# CC1312PSIP register map
File version: 1.0
CPU: CM4 1.0, other endian, MPU, FPU, 3 interrupt priority bits
Registers are 32-bit, read-write, reset 0x0 unless marked. A register's access mark holds for its fields unless they carry their own. Offsets are from the block's base; [hi:lo] are bit positions; {n}, {i} and the like mark numbered series; <NAME> marks a mode.

## AUX_ANAIF — AUX Analog Interface (AUX_ANAIF) encapsulates direct data and control interfaces between AUX digital and AUX analog circuits. It lets AUX_SCE, UDMA0, and system CPU: -Trigger ADC sample and conversion process. - Write ADC samples to FIFO. - Charge analog nodes by the use of the analog ISRC module. See ADI_4_AUX:ISRC and ADI_4_AUX:COMP.COMPA_REF_CURR_EN for further information. - Use the DAC to generate a programmable voltage on COMPB_REF, COMPA_REF, or COMPA_IN analog nodes. To use: - ADC : AUX_SCE must request active operational mode with AON_PMCTL:AUXSCECLK.SRC set to SCLK_HFDIV2. There are no requirements for system CPU. - ISRC : AUX_SCE must request active operational mode. There are no requirements for system CPU. - DAC : AUX_SCE must set AUX_SYSIF:PEROPRATE.ANAIF_DAC_OP_RATE to SCE_RATE as long as DAC state machine generates the sample clock. System CPU must set AUX_SYSIF:PEROPRATE.ANAIF_DAC_OP_RATE to BUS_RATE as long as DAC state machine generates the sample clock. See DACSMPLCTL.EN for further information.
Base 0x400C9000
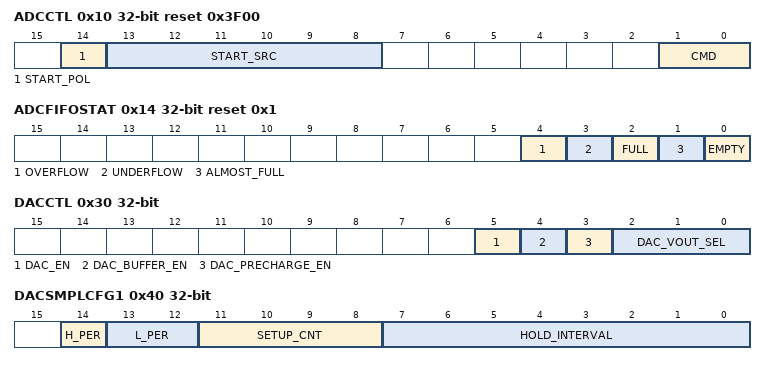
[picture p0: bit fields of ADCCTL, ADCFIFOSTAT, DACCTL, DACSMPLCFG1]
0x10 ADCCTL reset 0x3F00 — ADC Control Configuration of ADI_4_AUX:ADC0.SMPL_MODE decides if the ADC trigger starts sampling or conversion.
  [14] START_POL — [14:14] Select active polarity for START_SRC event.
    1=FALL (Set ADC trigger on falling edge of event source.); 0=RISE (Set ADC trigger on rising edge of event source.)
  [13:8] START_SRC — [13:8] Select ADC trigger event source from the asynchronous AUX event bus. Set START_SRC to NO_EVENT if you want to trigger the ADC manually through ADCTRIG.START. If you write a non-enumerated value the behavior is identical to NO_EVENT. The written value is returned when read.
    63=NO_EVENT; 61=AUX_SMPH_AUTOTAKE_DONE (AUX_EVCTL:EVSTAT3.AUX_SMPH_AUTOTAKE_DONE); 56=AUX_ISRC_RESET_N (AUX_EVCTL:EVSTAT3.AUX_ISRC_RESET_N); 55=AUX_TDC_DONE (AUX_EVCTL:EVSTAT3.AUX_TDC_DONE); 54=AUX_TIMER0_EV (AUX_EVCTL:EVSTAT3.AUX_TIMER0_EV); 53=AUX_TIMER1_EV (AUX_EVCTL:EVSTAT3.AUX_TIMER1_EV); 52=AUX_TIMER2_PULSE (AUX_EVCTL:EVSTAT3.AUX_TIMER2_PULSE); {v}=AUX_TIMER2_EV{v-48} (AUX_EVCTL:EVSTAT3.AUX_TIMER2_EV{v-48}) (v=48..51); 47=AUX_COMPB (AUX_EVCTL:EVSTAT2.AUX_COMPB); 46=AUX_COMPA (AUX_EVCTL:EVSTAT2.AUX_COMPA); 43=MCU_EV (AUX_EVCTL:EVSTAT2.MCU_EV); 42=ACLK_REF (AUX_EVCTL:EVSTAT2.ACLK_REF); 41=VDDR_RECHARGE (AUX_EVCTL:EVSTAT2.VDDR_RECHARGE); 40=MCU_ACTIVE (AUX_EVCTL:EVSTAT2.MCU_ACTIVE); 39=PWR_DWN (AUX_EVCTL:EVSTAT2.PWR_DWN); 38=SCLK_LF (AUX_EVCTL:EVSTAT2.SCLK_LF); 37=AON_BATMON_TEMP_UPD (AUX_EVCTL:EVSTAT2.AON_BATMON_TEMP_UPD); 36=AON_BATMON_BAT_UPD (AUX_EVCTL:EVSTAT2.AON_BATMON_BAT_UPD); 35=AON_RTC_4KHZ (AUX_EVCTL:EVSTAT2.AON_RTC_4KHZ); 34=AON_RTC_CH2_DLY (AUX_EVCTL:EVSTAT2.AON_RTC_CH2_DLY); 33=AON_RTC_CH2 (AUX_EVCTL:EVSTAT2.AON_RTC_CH2); 32=MANUAL_EV (AUX_EVCTL:EVSTAT2.MANUAL_EV); {v}=AUXIO{v} (AUX_EVCTL:EVSTAT1.AUXIO{v}) (v=16..31); {v}=AUXIO{v} (AUX_EVCTL:EVSTAT0.AUXIO{v}) (v=0..15)
  [1:0] CMD — [1:0] ADC interface command. Non-enumerated values are not supported. The written value is returned when read.
    3=FLUSH (Flush ADC FIFO. You must set CMD to EN or DIS after flush. System CPU must wait two clock cycles before it sets CMD to EN or DIS.); 1=EN (Enable ADC interface.); 0=DIS (Disable ADC interface.)
0x14 ADCFIFOSTAT reset 0x1 — ADC FIFO Status FIFO can hold up to four ADC samples.
  [4] OVERFLOW ro — [4:4] FIFO overflow flag. 0: FIFO has not overflowed. 1: FIFO has overflowed, this flag is sticky until you flush the FIFO. When the flag is set, the ADC FIFO write pointer is static. It is not possible to add more samples to the ADC FIFO. Flush FIFO to clear the flag.
  [3] UNDERFLOW ro — [3:3] FIFO underflow flag. 0: FIFO has not underflowed. 1: FIFO has underflowed, this flag is sticky until you flush the FIFO. When the flag is set, the ADC FIFO read pointer is static. Read returns the previous sample that was read. Flush FIFO to clear the flag.
  [2] FULL ro — [2:2] FIFO full flag. 0: FIFO is not full, there is less than 4 samples in the FIFO. 1: FIFO is full, there are 4 samples in the FIFO. When the flag is set, it is not possible to add more samples to the ADC FIFO. An attempt to add samples sets the OVERFLOW flag.
  [1] ALMOST_FULL ro — [1:1] FIFO almost full flag. 0: There are less than 3 samples in the FIFO, or the FIFO is full. The FULL flag is also asserted in the latter case. 1: There are 3 samples in the FIFO, there is room for one more sample.
  [0] EMPTY ro — [0:0] FIFO empty flag. 0: FIFO contains one or more samples. 1: FIFO is empty. When the flag is set, read returns the previous sample that was read and sets the UNDERFLOW flag.
0x18 ADCFIFO
  [11:0] DATA — [11:0] FIFO data. Read: Get oldest ADC sample from FIFO. Write: Write dummy sample to FIFO. This is useful for code development when you do not have real ADC samples.
0x1C ADCTRIG — ADC Trigger
  [0] START wo — [0:0] Manual ADC trigger. 0: No effect. 1: Single ADC trigger. To manually trigger the ADC, you must set ADCCTL.START_SRC to NO_EVENT to avoid conflict with event-driven ADC trigger.
0x20 ISRCCTL reset 0x1 — Current Source Control
  [0] RESET_N — [0:0] ISRC reset control. 0: ISRC drives 0 uA. 1: ISRC drives current ADI_4_AUX:ISRC.TRIM to COMPA_IN.
0x30 DACCTL — DAC Control This register controls the analog part of the DAC.
  [5] DAC_EN — [5:5] DAC module enable. 0: Disable DAC. 1: Enable DAC. The Sensor Controller must not use the DAC when AUX_SYSIF:OPMODEREQ.REQ equals PDA. The System CPU must not use the DAC when AUX_SYSIF:OPMODEREQ.REQ equals PDA in Standby TI-RTOS power mode. The System CPU must set AUX_SYSIF:PEROPRATE.ANAIF_DAC_OP_RATE to BUS_RATE to use the DAC in Active and Idle TI-RTOS power modes.
  [4] DAC_BUFFER_EN — [4:4] DAC buffer enable. DAC buffer reduces the time required to produce the programmed voltage at the expense of increased current consumption. 0: Disable DAC buffer. 1: Enable DAC buffer. Enable buffer when DAC_VOUT_SEL equals COMPA_IN. Do not enable the buffer when AUX_SYSIF:OPMODEREQ.REQ equals PDA or PDLP.
  [3] DAC_PRECHARGE_EN — [3:3] DAC precharge enable. Only enable precharge when ADI_4_AUX:MUX2.DAC_VREF_SEL equals DCOUPL and VDDS is higher than 2.65 V. DAC output voltage range: 0: 0 V to 1.28 V. 1: 1.28 V to 2.56 V. Otherwise, see ADI_4_AUX:MUX2.DAC_VREF_SEL for DAC output voltage range. Enable precharge 1 us before you enable the DAC and the buffer.
  [2:0] DAC_VOUT_SEL — [2:0] DAC output connection. An analog node must only have one driver. Other drivers for the following analog nodes are configured in [ANATOP_MMAP::ADI_4_AUX:*].
    4=COMPA_IN (Connect to COMPA_IN analog node. Required setting to drive external load selected in ADI_4_AUX:MUX1.COMPA_IN.); 2=COMPA_REF (Connect to COMPA_REF analog node. It is not possible to drive external loads connected to COMPA_REF I/O mux with this setting.); 1=COMPB_REF (Connect to COMPB_REF analog node. Required setting to use Comparator B.); 0=NC (Connect to nothing It is recommended to use NC as intermediate step when you change DAC_VOUT_SEL.)
0x34 LPMBIASCTL — Low Power Mode Bias Control The low power mode bias module provides bias current to DAC and Comparator A when AUX_SYSIF:OPMODEREQ.REQ differers from A.
  [0] EN — [0:0] Module enable. 0: Disable low power mode bias module. 1: Enable low power mode bias module. Set EN to 1 15 us before you enable the DAC or Comparator A.
0x38 DACSMPLCTL — DAC Sample Control The DAC sample clock maintains the DAC voltage stored in the sample-and-hold capacitor. The DAC sample clock waveform consists of a setup phase followed by a hold phase. In the setup phase the sample-and-hold capacitor charges to the programmed voltage. The hold phase maintains the voltage with minimal power. DACSMPLCFG0 and DACSMPLCFG1 configure the DAC sample clock waveform.
  [0] EN — [0:0] DAC sample clock enable. 0: Disable sample clock. The sample clock stops low and DACSTAT becomes 0 when the current sample clock period completes. 1: Enable DAC sample clock. DACSTAT must be 0 before you enable sample clock.
0x3C DACSMPLCFG0 — DAC Sample Configuration 0
  [5:0] CLKDIV — [5:0] Clock division. AUX_SYSIF:PEROPRATE.ANAIF_DAC_OP_RATE divided by (CLKDIV + 1) determines the sample clock base frequency. 0: Divide by 1. 1: Divide by 2. ... 63: Divide by 64.
0x40 DACSMPLCFG1 — DAC Sample Configuration 1 The sample clock period equals (high time + low time) * base period. DACSMPLCFG0.CLKDIV determines the base period. Timing requirements (DAC Buffer On / DAC Buffer Off): - (high time + low time) * base period > (4 us / 1 us) - (high time * base period) > (2 us / 0.5 us) - (low time * base period) > (2 us / 0.5 us) - (low time * base period + HOLD_INTERVAL * sample clock period) < 32 us If AUX_SYSIF:OPMODEREQ.REQ equals PDLP, you must set: - H_PER = L_PER = HOLD_INTERVAL = 0.
  [14] H_PER — [14:14] High time. The sample clock period is high for this many base periods. 0: 2 periods 1: 4 periods
  [13:12] L_PER — [13:12] Low time. The sample clock period is low for this many base periods. 0: 1 period 1: 2 periods 2: 3 periods 3: 4 periods
  [11:8] SETUP_CNT — [11:8] Setup count. Number of active sample clock periods during the setup phase. 0: 1 sample clock period 1: 2 sample clock periods ... 15 : 16 sample clock periods
  [7:0] HOLD_INTERVAL — [7:0] Hold interval. Number of inactive sample clock periods between each active sample clock period during hold phase. The sample clock is low when inactive. The range is 0 to 255.
0x44 DACVALUE
  [7:0] VALUE — [7:0] DAC value. Digital data word for the DAC. Only change VALUE when DACCTL.DAC_EN is 0. Then wait 1 us before you enable the DAC.
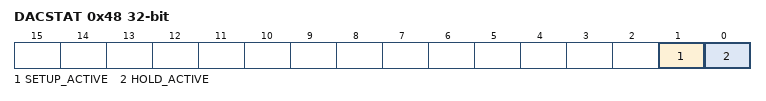
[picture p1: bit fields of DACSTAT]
0x48 DACSTAT — DAC Status
  [1] SETUP_ACTIVE ro — [1:1] DAC setup phase status. 0: Sample clock is disabled or setup phase is complete. 1: Setup phase in progress.
  [0] HOLD_ACTIVE ro — [0:0] DAC hold phase status. 0: Sample clock is disabled or DAC is not in hold phase. 1: Hold phase in progress.
